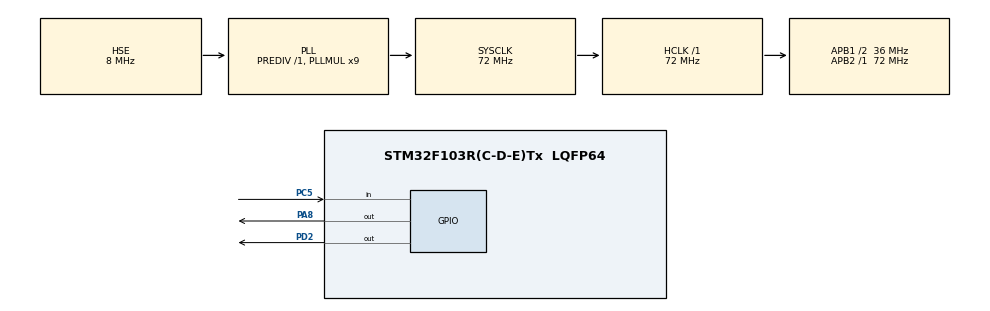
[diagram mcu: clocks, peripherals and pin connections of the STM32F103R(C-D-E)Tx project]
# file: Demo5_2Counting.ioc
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FREERTOS.CountingSemaphores01=Sem_Tables,5,Dynamic,NULL
FREERTOS.Tasks01=Task_Checkln,24,128,AppTask_Checkln,Default,NULL,Dynamic,NULL,NULL
Mcu.Family=STM32F1
Mcu.Name=STM32F103R(C-D-E)Tx
Mcu.Package=LQFP64
NVIC.PriorityGroup=NVIC_PRIORITYGROUP_4
NVIC.RTC_IRQn=true\:5\:0\:false\:false\:true\:true\:true\:true\:true
NVIC.TIM6_IRQn=true\:15\:0\:false\:false\:true\:false\:false\:true\:true
NVIC.TimeBase=TIM6_IRQn
NVIC.TimeBaseIP=TIM6
PA13.Mode=Serial_Wire
PA13.Signal=SYS_JTMS-SWDIO
PA14.Mode=Serial_Wire
PA14.Signal=SYS_JTCK-SWCLK
PA8.Signal=GPIO_Output
PC14-OSC32_IN.Mode=LSE-External-Oscillator
PC14-OSC32_IN.Signal=RCC_OSC32_IN
PC15-OSC32_OUT.Mode=LSE-External-Oscillator
PC15-OSC32_OUT.Signal=RCC_OSC32_OUT
PC5.GPIO_PuPd=GPIO_PULLUP
PC5.Signal=GPIO_Input
PD0-OSC_IN.Mode=HSE-External-Oscillator
PD0-OSC_IN.Signal=RCC_OSC_IN
PD1-OSC_OUT.Mode=HSE-External-Oscillator
PD1-OSC_OUT.Signal=RCC_OSC_OUT
PD2.Signal=GPIO_Output
ProjectManager.HeapSize=0x200
ProjectManager.StackSize=0x400
ProjectManager.TargetToolchain=SW4STM32
RCC.AHBFreq_Value=72000000
RCC.APB1CLKDivider=RCC_HCLK_DIV2
RCC.APB1Freq_Value=36000000
RCC.APB1TimFreq_Value=72000000
RCC.APB2Freq_Value=72000000
RCC.APB2TimFreq_Value=72000000
RCC.HCLKFreq_Value=72000000
RCC.PLLMUL=RCC_PLL_MUL9
RCC.PLLSourceVirtual=RCC_PLLSOURCE_HSE
RCC.SYSCLKFreq_VALUE=72000000
RCC.SYSCLKSource=RCC_SYSCLKSOURCE_PLLCLK
RCC.USBFreq_Value=72000000
VP_FREERTOS_VS_CMSIS_V2.Mode=CMSIS_V2
VP_RTC_VS_RTC_Activate.Mode=RTC_Enabled
VP_RTC_VS_RTC_Calendar.Mode=RTC_Calendar
VP_SYS_VS_tim6.Mode=TIM6
board=custom

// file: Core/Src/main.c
/* USER CODE BEGIN Header */
/**
  ******************************************************************************
  * @file           : main.c
  * @brief          : Main program body
  ******************************************************************************
  * @attention
  *
  * Copyright (c) 2022 STMicroelectronics.
  * All rights reserved.
  *
  * This software is licensed under terms that can be found in the LICENSE file
  * in the root directory of this software component.
  * If no LICENSE file comes with this software, it is provided AS-IS.
  *
  ******************************************************************************
  */
/* USER CODE END Header */
#include "main.h"
#include "cmsis_os.h"
#include "rtc.h"
#include "gpio.h"

/* USER CODE BEGIN Includes */
#include "lcd.h"
/* USER CODE END Includes */

void SystemClock_Config(void);
void MX_FREERTOS_Init(void);

int main(void)
{

  /* MCU Configuration--------------------------------------------------------*/

  /* Reset of all peripherals, Initializes the Flash interface and the Systick. */
  HAL_Init();

  /* USER CODE BEGIN Init */
  LCD_Init();
  /* USER CODE END Init */

  /* Configure the system clock */
  SystemClock_Config();

  /* Initialize all configured peripherals */
  MX_GPIO_Init();
  MX_RTC_Init();
  /* USER CODE BEGIN 2 */
  POINT_COLOR=BLUE;
  LCD_ShowString(20,20,160,24,16,(uint8_t* )"Demo5_2Counting");
  /* USER CODE END 2 */

  /* Init scheduler */
  osKernelInitialize();  /* Call init function for freertos objects (in freertos.c) */
  MX_FREERTOS_Init();

  /* Start scheduler */
  osKernelStart();

  /* We should never get here as control is now taken by the scheduler */
  /* Infinite loop */
  while (1)
  {

  }
}

void SystemClock_Config(void)
{
  RCC_OscInitTypeDef RCC_OscInitStruct = {0};
  RCC_ClkInitTypeDef RCC_ClkInitStruct = {0};
  RCC_PeriphCLKInitTypeDef PeriphClkInit = {0};

  /** Initializes the RCC Oscillators according to the specified parameters
  * in the RCC_OscInitTypeDef structure.
  */
  RCC_OscInitStruct.OscillatorType = RCC_OSCILLATORTYPE_LSI|RCC_OSCILLATORTYPE_HSE;
  RCC_OscInitStruct.HSEState = RCC_HSE_ON;
  RCC_OscInitStruct.HSEPredivValue = RCC_HSE_PREDIV_DIV1;
  RCC_OscInitStruct.HSIState = RCC_HSI_ON;
  RCC_OscInitStruct.LSIState = RCC_LSI_ON;
  RCC_OscInitStruct.PLL.PLLState = RCC_PLL_ON;
  RCC_OscInitStruct.PLL.PLLSource = RCC_PLLSOURCE_HSE;
  RCC_OscInitStruct.PLL.PLLMUL = RCC_PLL_MUL9;
  if (HAL_RCC_OscConfig(&RCC_OscInitStruct) != HAL_OK)
  {
    Error_Handler();
  }

  /** Initializes the CPU, AHB and APB buses clocks
  */
  RCC_ClkInitStruct.ClockType = RCC_CLOCKTYPE_HCLK|RCC_CLOCKTYPE_SYSCLK
                              |RCC_CLOCKTYPE_PCLK1|RCC_CLOCKTYPE_PCLK2;
  RCC_ClkInitStruct.SYSCLKSource = RCC_SYSCLKSOURCE_PLLCLK;
  RCC_ClkInitStruct.AHBCLKDivider = RCC_SYSCLK_DIV1;
  RCC_ClkInitStruct.APB1CLKDivider = RCC_HCLK_DIV2;
  RCC_ClkInitStruct.APB2CLKDivider = RCC_HCLK_DIV1;

  if (HAL_RCC_ClockConfig(&RCC_ClkInitStruct, FLASH_LATENCY_2) != HAL_OK)
  {
    Error_Handler();
  }
  PeriphClkInit.PeriphClockSelection = RCC_PERIPHCLK_RTC;
  PeriphClkInit.RTCClockSelection = RCC_RTCCLKSOURCE_LSI;
  if (HAL_RCCEx_PeriphCLKConfig(&PeriphClkInit) != HAL_OK)
  {
    Error_Handler();
  }
}

void HAL_TIM_PeriodElapsedCallback(TIM_HandleTypeDef *htim)
{
  if (htim->Instance == TIM6) {
    HAL_IncTick();
  }
}

void Error_Handler(void)
{
  __disable_irq();
  while (1)
  {
  }
}

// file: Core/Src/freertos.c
/* USER CODE BEGIN Header */
/**
  ******************************************************************************
  * File Name          : freertos.c
  * Description        : Code for freertos applications
  ******************************************************************************
  * @attention
  *
  * Copyright (c) 2022 STMicroelectronics.
  * All rights reserved.
  *
  * This software is licensed under terms that can be found in the LICENSE file
  * in the root directory of this software component.
  * If no LICENSE file comes with this software, it is provided AS-IS.
  *
  ******************************************************************************
  */
/* USER CODE END Header */

#include "FreeRTOS.h"
#include "task.h"
#include "main.h"
#include "cmsis_os.h"

/* USER CODE BEGIN Includes */
#include "lcd.h"
#include "semphr.h"
/* USER CODE END Includes */

/* Definitions for Task_Checkln */
osThreadId_t Task_ChecklnHandle;
const osThreadAttr_t Task_Checkln_attributes = {
  .name = "Task_Checkln",
  .stack_size = 128 * 4,
  .priority = (osPriority_t) osPriorityNormal,
};
/* Definitions for Sem_Tables */
osSemaphoreId_t Sem_TablesHandle;
const osSemaphoreAttr_t Sem_Tables_attributes = {
  .name = "Sem_Tables"
};

void AppTask_Checkln(void *argument);

void MX_FREERTOS_Init(void); /* (MISRA C 2004 rule 8.1) */

void MX_FREERTOS_Init(void) {

  /* Create the semaphores(s) */
  /* creation of Sem_Tables */
  Sem_TablesHandle = osSemaphoreNew(5, 5, &Sem_Tables_attributes);

  /* Create the thread(s) */
  /* creation of Task_Checkln */
  Task_ChecklnHandle = osThreadNew(AppTask_Checkln, NULL, &Task_Checkln_attributes);

}

void AppTask_Checkln(void *argument)
{
  /* USER CODE BEGIN AppTask_Checkln */
  UBaseType_t totalTables= uxSemaphoreGetCount(Sem_TablesHandle);
  LCD_ShowString(20,50,160,24,16,(uint8_t *)"Total tables= ");
  LCD_ShowNum(160,50,totalTables,2,16);
  LCD_ShowString(20,80,160,24,16,(uint8_t *)"Available tables= ");

  /* Infinite loop */
  for(;;)
  {
    GPIO_PinState keyState= HAL_GPIO_ReadPin(GPIOC,GPIO_PIN_5);
    if(keyState==GPIO_PIN_RESET)
    {
      BaseType_t result= xSemaphoreTake(Sem_TablesHandle, pdMS_TO_TICKS(100));
      if(result==pdTRUE)
      {
        LCD_ShowString(20,100,160,24,16,(uint8_t *)"Check in OK ");
      }
      else
        LCD_ShowString(20,120,160,24,16,(uint8_t *)"Check in fail ");
      vTaskDelay(pdMS_TO_TICKS(300));
    }
    UBaseType_t availableTables= uxSemaphoreGetCount(Sem_TablesHandle);
    LCD_ShowNum(160,80,availableTables,2,16);
    vTaskDelay(pdMS_TO_TICKS(10));
  }
  /* USER CODE END AppTask_Checkln */
}
